VERSION ""

NS_ :

BS_:

BU_: PDM

BO_ 2565821696 Control: 8 Vector__XXX
 SG_ Mux M : 0|4@1+ (1,0) [0|15] "" Vector__XXX
 SG_ Output_1 m0 : 4|2@1+ (1,0) [0|3] "High-current output 1" Vector__XXX
 SG_ Output_2 m0 : 6|2@1+ (1,0) [0|3] "High-current output 2" Vector__XXX
 SG_ Output_3 m0 : 8|2@1+ (1,0) [0|3] "Output 3" Vector__XXX
 SG_ Output_4 m0 : 10|2@1+ (1,0) [0|3] "Output 4" Vector__XXX
 SG_ Output_5 m0 : 12|2@1+ (1,0) [0|3] "Output 5" Vector__XXX
 SG_ Output_6 m0 : 14|2@1+ (1,0) [0|3] "Output 6" Vector__XXX
 SG_ Output_7 m0 : 16|2@1+ (1,0) [0|3] "Output 7" Vector__XXX
 SG_ Output_8 m0 : 18|2@1+ (1,0) [0|3] "Output 8" Vector__XXX
 SG_ Output_9 m0 : 20|2@1+ (1,0) [0|3] "Output 9" Vector__XXX
 SG_ Output_10 m0 : 22|2@1+ (1,0) [0|3] "Output 10" Vector__XXX
 SG_ Output_11 m0 : 24|2@1+ (1,0) [0|3] "Output 11" Vector__XXX
 SG_ Output_12 m0 : 26|2@1+ (1,0) [0|3] "Output 12" Vector__XXX
 SG_ Output_13 m0 : 28|2@1+ (1,0) [0|3] "Output 13" Vector__XXX
 SG_ Output_14 m0 : 30|2@1+ (1,0) [0|3] "Output 14" Vector__XXX
 SG_ Output_15 m0 : 32|2@1+ (1,0) [0|3] "Output 15" Vector__XXX
 SG_ Output_16 m0 : 34|2@1+ (1,0) [0|3] "Output 16" Vector__XXX
 SG_ Output_17 m0 : 36|2@1+ (1,0) [0|3] "Output 17" Vector__XXX
 SG_ Output_18 m0 : 38|2@1+ (1,0) [0|3] "Output 18" Vector__XXX
 SG_ Output_19 m0 : 40|2@1+ (1,0) [0|3] "High-current output 19" Vector__XXX
 SG_ Output_20 m0 : 42|2@1+ (1,0) [0|3] "High-current output 20" Vector__XXX
 SG_ PWM_Duty m0 : 44|8@1+ (1,0) [0|255] "PWM duty" Vector__XXX

BO_ 2582597632 Configure: 8 Vector__XXX
 SG_ Mux M : 0|4@1+ (1,0) [0|15] "" Vector__XXX
 SG_ System_Restart m0 : 4|2@1+ (1,0) [0|3] "Perform a firmware restart after applying configuration" Vector__XXX
 SG_ System_Reset m0 : 6|2@1+ (1,0) [0|3] "Reset all configuration to factory defaults" Vector__XXX
 SG_ CAN_Bitrate m1 : 4|4@1+ (1,0) [0|255] "CAN bitrate" Vector__XXX
 SG_ CAN_J1939_Source_Address m1 : 8|8@1+ (1,0) [1|255] "J1939 source address" Vector__XXX
 SG_ Output_Channel m2 : 4|8@1+ (1,0) [1|20] "Output channel selection" Vector__XXX
 SG_ Output_Econ_Delay m2 : 12|8@1+ (1,0) [0|255] "Output economisation delay in 10-milliseconds (zero = disable)" Vector__XXX
 SG_ Output_Econ_Duty m2 : 20|8@1+ (1,0) [0|255] "Output economisation duty" Vector__XXX
 SG_ Output_Heartbeat_Duration m2 : 28|8@1+ (1,0) [0|255] "Output heartbeat duration in 100-milliseconds (zero = disable)" Vector__XXX

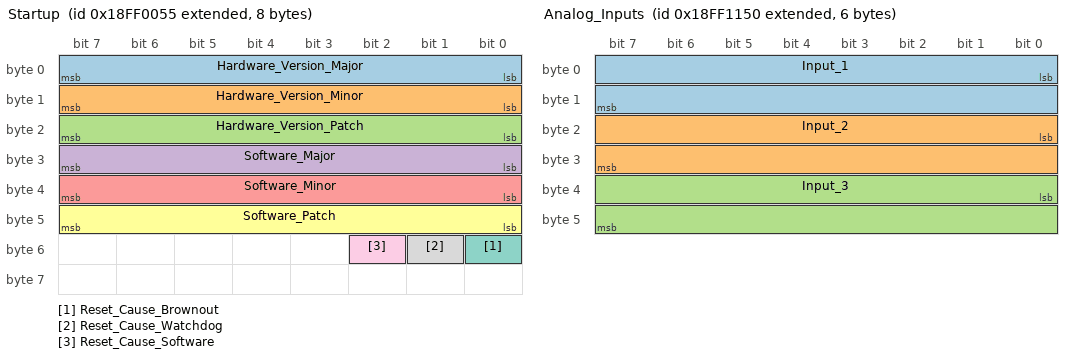
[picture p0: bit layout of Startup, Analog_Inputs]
BO_ 2566848597 Startup: 8 Vector__XXX
 SG_ Hardware_Version_Major : 0|8@1+ (1,0) [0|255] "SemVer" Vector__XXX
 SG_ Hardware_Version_Minor : 8|8@1+ (1,0) [0|255] "SemVer" Vector__XXX
 SG_ Hardware_Version_Patch : 16|8@1+ (1,0) [0|255] "SemVer" Vector__XXX
 SG_ Software_Major : 24|8@1+ (1,0) [0|255] "SemVer" Vector__XXX
 SG_ Software_Minor : 32|8@1+ (1,0) [0|255] "SemVer" Vector__XXX
 SG_ Software_Patch : 40|8@1+ (1,0) [0|255] "SemVer" Vector__XXX
 SG_ Reset_Cause_Brownout : 48|1@1+ (1,0) [0|1] "Boolean" Vector__XXX
 SG_ Reset_Cause_Watchdog : 49|1@1+ (1,0) [0|1] "Boolean" Vector__XXX
 SG_ Reset_Cause_Software : 50|1@1+ (1,0) [0|1] "Boolean" Vector__XXX

BO_ 2566853205 System_Status: 8 Vector__XXX
 SG_ CAN_RX_Errors : 8|8@1+ (1,0) [0|255] "Count" Vector__XXX
 SG_ CAN_TX_Errors : 16|8@1+ (1,0) [0|255] "Count" Vector__XXX

BO_ 2566852944 Analog_Inputs: 6 Vector__XXX
 SG_ Input_1 : 0|16@1+ (1,0) [0|65535] "Analog input 1" Vector__XXX
 SG_ Input_2 : 16|16@1+ (1,0) [0|65535] "Analog input 2" Vector__XXX
 SG_ Input_3 : 32|16@1+ (1,0) [0|65535] "Analog input 3" Vector__XXX

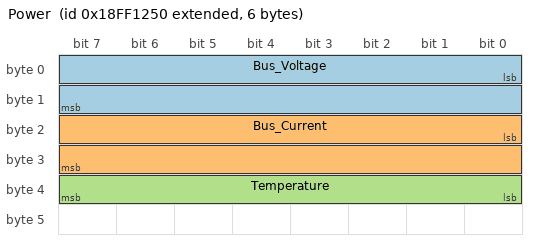
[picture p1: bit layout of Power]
BO_ 2566853200 Power: 6 Vector__XXX
 SG_ Bus_Voltage : 0|16@1+ (1,0) [0|65535] "Bus voltage in Volts" Vector__XXX
 SG_ Bus_Current : 16|16@1+ (1,0) [0|65535] "Bus current in Amps" Vector__XXX
 SG_ Temperature : 32|8@1+ (1,0) [0|255] "Celsius" Vector__XXX

BO_ 2566853456 Current_Sense: 8 Vector__XXX
 SG_ mux M : 0|4@1+ (1,0) [0|15] "" Vector__XXX
 SG_ Current_Sense_1 m0 : 4|8@1+ (1,0) [0|255] "Output 1 current sense" Vector__XXX
 SG_ Current_Sense_2 m0 : 12|8@1+ (1,0) [0|255] "Output 2 current sense" Vector__XXX
 SG_ Current_Sense_3 m0 : 20|8@1+ (1,0) [0|255] "Output 3 current sense" Vector__XXX
 SG_ Current_Sense_4 m0 : 28|8@1+ (1,0) [0|255] "Output 4 current sense" Vector__XXX
 SG_ Current_Sense_5 m0 : 36|8@1+  (1,0) [0|255] "Output 5 current sense" Vector__XXX
 SG_ Current_Sense_6 m0 : 44|8@1+ (1,0) [0|255] "Output 6 current sense" Vector__XXX
 SG_ Current_Sense_7 m1 : 4|8@1+ (1,0) [0|255] "Output 7 current sense" Vector__XXX
 SG_ Current_Sense_8 m1 : 12|8@1+ (1,0) [0|255] "Output 8 current sense" Vector__XXX
 SG_ Current_Sense_9 m1 : 20|8@1+ (1,0) [0|255] "Output 9 current sense" Vector__XXX
 SG_ Current_Sense_10 m1 : 28|8@1+ (1,0) [0|255] "Output 10 current sense" Vector__XXX
 SG_ Current_Sense_11 m1 : 36|8@1+ (1,0) [0|255] "Output 11 current sense" Vector__XXX
 SG_ Current_Sense_12 m1 : 44|8@1+ (1,0) [0|255] "Output 12 current sense" Vector__XXX
 SG_ Current_Sense_13 m2 : 4|8@1+ (1,0) [0|255] "Output 13 current sense" Vector__XXX
 SG_ Current_Sense_14 m2 : 12|8@1+ (1,0) [0|255] "Output 14 current sense" Vector__XXX
 SG_ Current_Sense_15 m2 : 20|8@1+ (1,0) [0|255] "Output 15 current sense" Vector__XXX
 SG_ Current_Sense_16 m2 : 28|8@1+ (1,0) [0|255] "Output 16 current sense" Vector__XXX
 SG_ Current_Sense_17 m2 : 36|8@1+ (1,0) [0|255] "Output 17 current sense" Vector__XXX
 SG_ Current_Sense_18 m2 : 44|8@1+ (1,0) [0|255] "Output 18 current sense" Vector__XXX
 SG_ Current_Sense_19 m3 : 4|8@1+ (1,0) [0|255] "Output 19 current sense" Vector__XXX
 SG_ Current_Sense_20 m3 : 12|8@1+ (1,0) [0|255] "Output 20 current sense" Vector__XXX

VAL_ 2582597632 CAN_Bitrate 0 "500 kBit/s" 1 "50 kBit/s" 2 "100 kBit/s" 3 "125 kBit/s" 4 "250 kBit/s" 5 "1 MBit/s" 255 "No change";
